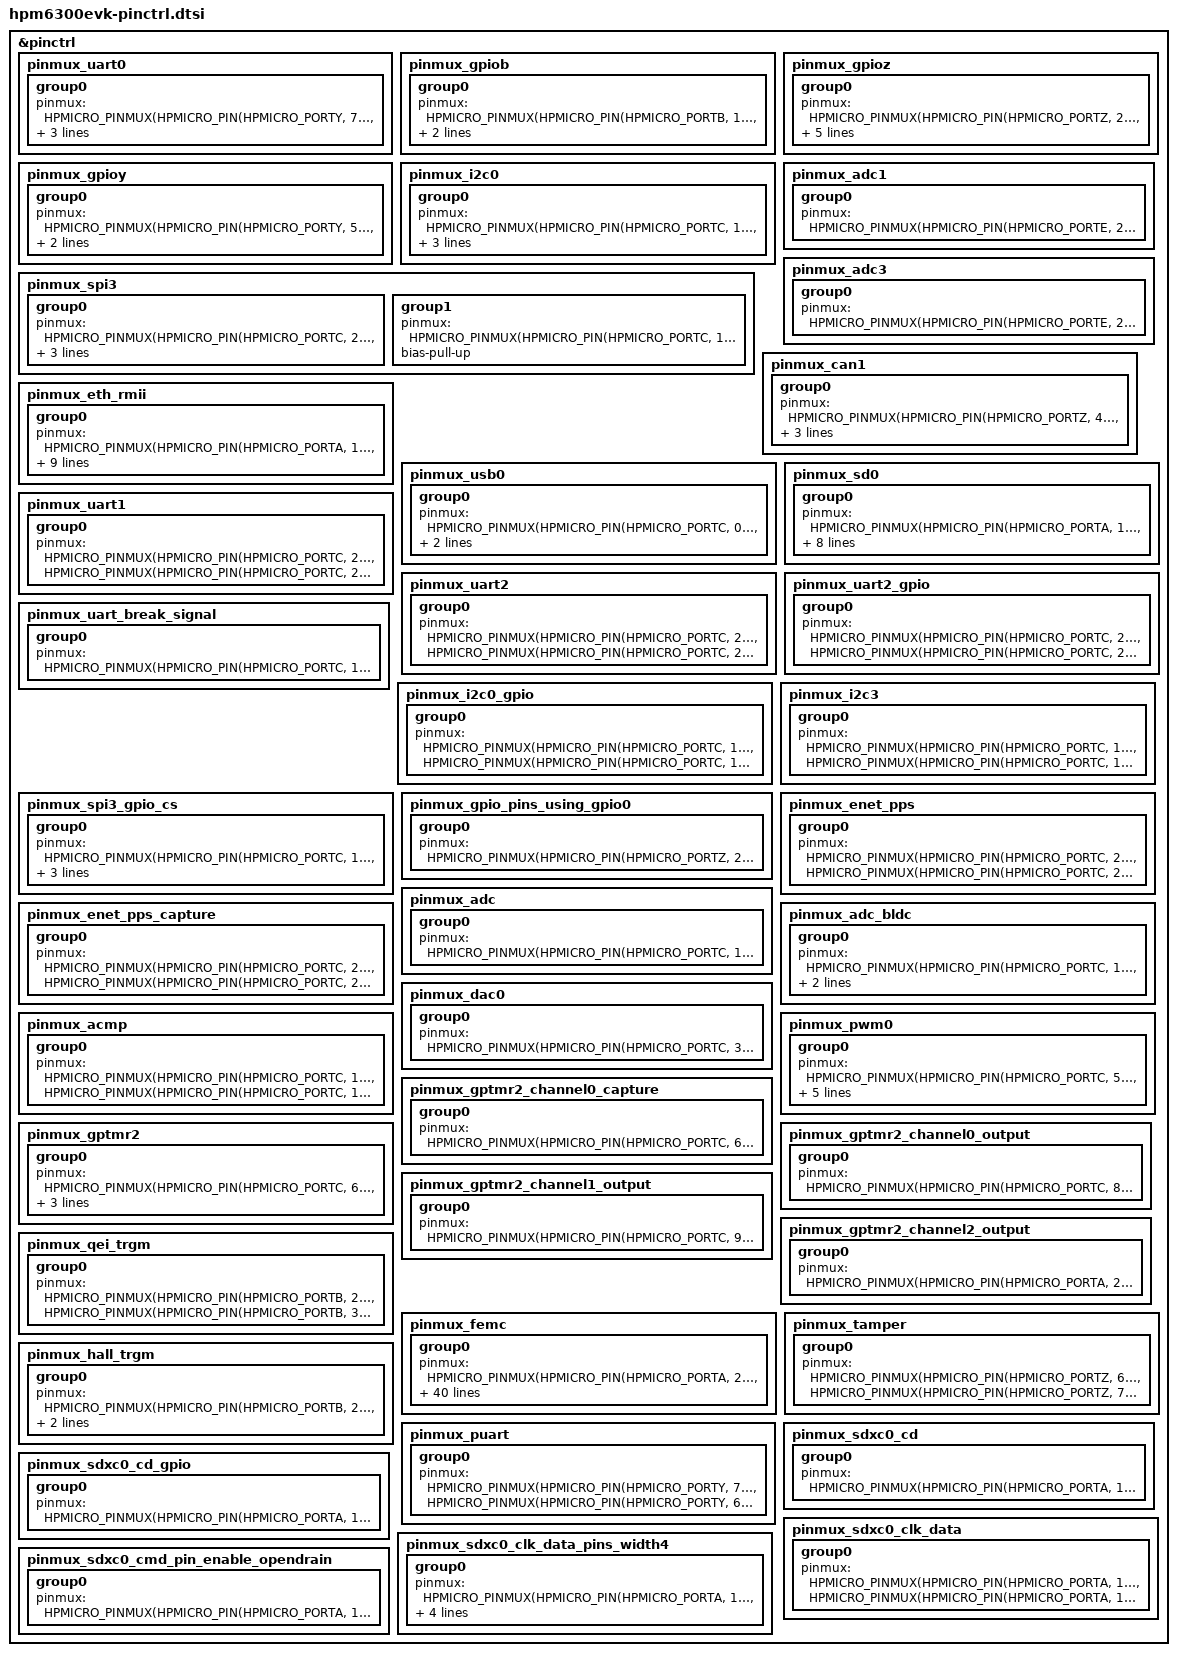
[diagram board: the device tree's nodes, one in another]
/*
* Copyright (c) 2026 HPMicro
* SPDX-License-Identifier: Apache-2.0
*/

#include "dt-bindings/pinctrl/hpmicro-pinctrl-common.h"

&pinctrl {
	pinmux_uart0: pinmux_uart0 {
		group0 {
			pinmux = <HPMICRO_PINMUX(HPMICRO_PIN(HPMICRO_PORTY, 7), IOC_TYPE_IOC, 0, 2)>,
				<HPMICRO_PINMUX(HPMICRO_PIN(HPMICRO_PORTY, 6), IOC_TYPE_IOC, 0, 2)>,
				<HPMICRO_PINMUX(HPMICRO_PIN(HPMICRO_PORTY, 7), IOC_TYPE_PIOC, 0, 3)>,
				<HPMICRO_PINMUX(HPMICRO_PIN(HPMICRO_PORTY, 6), IOC_TYPE_PIOC, 0, 3)>;
		};
	};

	pinmux_gpiob: pinmux_gpiob {
		group0 {
			pinmux = <HPMICRO_PINMUX(HPMICRO_PIN(HPMICRO_PORTB, 1), IOC_TYPE_IOC, 0, 0)>,
				<HPMICRO_PINMUX(HPMICRO_PIN(HPMICRO_PORTB, 19), IOC_TYPE_IOC, 0, 0)>;
			bias-pull-down;
		};
	};

	pinmux_gpioz: pinmux_gpioz {
		group0 {
			pinmux = <HPMICRO_PINMUX(HPMICRO_PIN(HPMICRO_PORTZ, 2), IOC_TYPE_IOC, 0, 0)>,
				<HPMICRO_PINMUX(HPMICRO_PIN(HPMICRO_PORTZ, 2), IOC_TYPE_BIOC, 0, 3)>;
			bias-pull-up;
			input-enable;
			keeper-capability-disable;
			input-schmitt-enable;
		};
	};

	pinmux_gpioy: pinmux_gpioy {
		group0 {
			pinmux = <HPMICRO_PINMUX(HPMICRO_PIN(HPMICRO_PORTY, 5), IOC_TYPE_IOC, 0, 0)>,
				<HPMICRO_PINMUX(HPMICRO_PIN(HPMICRO_PORTY, 5), IOC_TYPE_BIOC, 0, 3)>;
			bias-pull-up;
		};
	};

	pinmux_i2c0: pinmux_i2c0 {
		group0 {
			pinmux = <HPMICRO_PINMUX(HPMICRO_PIN(HPMICRO_PORTC, 13), IOC_TYPE_IOC, 0, 4)>,
				<HPMICRO_PINMUX(HPMICRO_PIN(HPMICRO_PORTC, 14), IOC_TYPE_IOC, 0, 4)>;
			drive-open-drain;
			input-enable;
		};
	};

	pinmux_spi3: pinmux_spi3 {
		group0 {
			pinmux = <HPMICRO_PINMUX(HPMICRO_PIN(HPMICRO_PORTC, 21), IOC_TYPE_IOC, 0, 5)>,
				<HPMICRO_PINMUX(HPMICRO_PIN(HPMICRO_PORTC, 19), IOC_TYPE_IOC, 0, 5)>,
				<HPMICRO_PINMUX(HPMICRO_PIN(HPMICRO_PORTC, 20), IOC_TYPE_IOC, 0, 5)>;
			input-enable;
		};

		group1 {
			pinmux = <HPMICRO_PINMUX(HPMICRO_PIN(HPMICRO_PORTC, 18), IOC_TYPE_IOC, 0, 0)>;
			bias-pull-up;
		};
	};

	pinmux_adc1: pinmux_adc1 {
		group0 {
			pinmux = <HPMICRO_PINMUX(HPMICRO_PIN(HPMICRO_PORTE, 21), IOC_TYPE_IOC, 1, 0)>;
		};
	};

	pinmux_adc3: pinmux_adc3 {
		group0 {
			pinmux = <HPMICRO_PINMUX(HPMICRO_PIN(HPMICRO_PORTE, 29), IOC_TYPE_IOC, 1, 0)>;
		};
	};

	pinmux_can1: pinmux_can1 {
		group0 {
			pinmux = <HPMICRO_PINMUX(HPMICRO_PIN(HPMICRO_PORTZ, 4), IOC_TYPE_IOC, 0, 7)>,
				<HPMICRO_PINMUX(HPMICRO_PIN(HPMICRO_PORTZ, 5), IOC_TYPE_IOC, 0, 7)>,
				<HPMICRO_PINMUX(HPMICRO_PIN(HPMICRO_PORTZ, 4), IOC_TYPE_BIOC, 0, 3)>,
				<HPMICRO_PINMUX(HPMICRO_PIN(HPMICRO_PORTZ, 5), IOC_TYPE_BIOC, 0, 3)>;
		};
	};

	pinmux_eth_rmii: pinmux_eth_rmii {
		group0 {
			pinmux = <HPMICRO_PINMUX(HPMICRO_PIN(HPMICRO_PORTA, 16), IOC_TYPE_IOC, 0, 19)>,
				<HPMICRO_PINMUX(HPMICRO_PIN(HPMICRO_PORTA, 15), IOC_TYPE_IOC, 0, 19)>,
				<HPMICRO_PINMUX(HPMICRO_PIN(HPMICRO_PORTA, 18), IOC_TYPE_IOC, 0, 18)>,
				<HPMICRO_PINMUX(HPMICRO_PIN(HPMICRO_PORTA, 17), IOC_TYPE_IOC, 0, 18)>,
				<HPMICRO_PINMUX(HPMICRO_PIN(HPMICRO_PORTA, 19), IOC_TYPE_IOC, 0, 18)>,
				<HPMICRO_PINMUX(HPMICRO_PIN(HPMICRO_PORTA, 20), IOC_TYPE_IOC, 0, 18)>,
				<HPMICRO_PINMUX(HPMICRO_PIN(HPMICRO_PORTA, 21), IOC_TYPE_IOC, 0, 18)>,
				<HPMICRO_PINMUX(HPMICRO_PIN(HPMICRO_PORTA, 23), IOC_TYPE_IOC, 0, 18)>,
				<HPMICRO_PINMUX(HPMICRO_PIN(HPMICRO_PORTA, 22), IOC_TYPE_IOC, 0, 18)>;
			input-enable;
		};
	};

	pinmux_usb0: pinmux_usb0 {
		group0 {
			pinmux = <HPMICRO_PINMUX(HPMICRO_PIN(HPMICRO_PORTC, 0), IOC_TYPE_IOC, 0, 24)>,
				<HPMICRO_PINMUX(HPMICRO_PIN(HPMICRO_PORTC, 1), IOC_TYPE_IOC, 0, 24)>,
				<HPMICRO_PINMUX(HPMICRO_PIN(HPMICRO_PORTC, 2), IOC_TYPE_IOC, 0, 24)>;
		};
	};

	pinmux_sd0: pinmux_sd0 {
		group0 {
			pinmux = <HPMICRO_PINMUX(HPMICRO_PIN(HPMICRO_PORTA, 10), IOC_TYPE_IOC, 0, 17)>,
				<HPMICRO_PINMUX(HPMICRO_PIN(HPMICRO_PORTA, 11), IOC_TYPE_IOC, 0, 17)>,
				<HPMICRO_PINMUX(HPMICRO_PIN(HPMICRO_PORTA, 12), IOC_TYPE_IOC, 0, 17)>,
				<HPMICRO_PINMUX(HPMICRO_PIN(HPMICRO_PORTA, 13), IOC_TYPE_IOC, 0, 17)>,
				<HPMICRO_PINMUX(HPMICRO_PIN(HPMICRO_PORTA, 8), IOC_TYPE_IOC, 0, 17)>,
				<HPMICRO_PINMUX(HPMICRO_PIN(HPMICRO_PORTA, 9), IOC_TYPE_IOC, 0, 17)>;
			input-enable;
			bias-pull-up;
			drive-strength = "r111";
		};
	};

	pinmux_uart1: pinmux_uart1 {
		group0 {
			pinmux = <HPMICRO_PINMUX(HPMICRO_PIN(HPMICRO_PORTC, 24), IOC_TYPE_IOC, 0, 2)>,
				<HPMICRO_PINMUX(HPMICRO_PIN(HPMICRO_PORTC, 25), IOC_TYPE_IOC, 0, 2)>;
		};
	};

	pinmux_uart2: pinmux_uart2 {
		group0 {
			pinmux = <HPMICRO_PINMUX(HPMICRO_PIN(HPMICRO_PORTC, 26), IOC_TYPE_IOC, 0, 2)>,
				<HPMICRO_PINMUX(HPMICRO_PIN(HPMICRO_PORTC, 27), IOC_TYPE_IOC, 0, 2)>;
		};
	};

	pinmux_uart2_gpio: pinmux_uart2_gpio {
		group0 {
			pinmux = <HPMICRO_PINMUX(HPMICRO_PIN(HPMICRO_PORTC, 26), IOC_TYPE_IOC, 0, 0)>,
				<HPMICRO_PINMUX(HPMICRO_PIN(HPMICRO_PORTC, 27), IOC_TYPE_IOC, 0, 0)>;
		};
	};

	pinmux_uart_break_signal: pinmux_uart_break_signal {
		group0 {
			pinmux = <HPMICRO_PINMUX(HPMICRO_PIN(HPMICRO_PORTC, 18), IOC_TYPE_IOC, 0, 0)>;
		};
	};

	pinmux_i2c0_gpio: pinmux_i2c0_gpio {
		group0 {
			pinmux = <HPMICRO_PINMUX(HPMICRO_PIN(HPMICRO_PORTC, 13), IOC_TYPE_IOC, 0, 0)>,
				<HPMICRO_PINMUX(HPMICRO_PIN(HPMICRO_PORTC, 14), IOC_TYPE_IOC, 0, 0)>;
		};
	};

	pinmux_i2c3: pinmux_i2c3 {
		group0 {
			pinmux = <HPMICRO_PINMUX(HPMICRO_PIN(HPMICRO_PORTC, 11), IOC_TYPE_IOC, 0, 4)>,
				<HPMICRO_PINMUX(HPMICRO_PIN(HPMICRO_PORTC, 12), IOC_TYPE_IOC, 0, 4)>;
		};
	};

	pinmux_spi3_gpio_cs: pinmux_spi3_gpio_cs {
		group0 {
			pinmux = <HPMICRO_PINMUX(HPMICRO_PIN(HPMICRO_PORTC, 18), IOC_TYPE_IOC, 0, 0)>,
				<HPMICRO_PINMUX(HPMICRO_PIN(HPMICRO_PORTC, 21), IOC_TYPE_IOC, 0, 5)>,
				<HPMICRO_PINMUX(HPMICRO_PIN(HPMICRO_PORTC, 19), IOC_TYPE_IOC, 0, 5)>,
				<HPMICRO_PINMUX(HPMICRO_PIN(HPMICRO_PORTC, 20), IOC_TYPE_IOC, 0, 5)>;
		};
	};

	pinmux_gpio_pins_using_gpio0: pinmux_gpio_pins_using_gpio0 {
		group0 {
			pinmux =
				<HPMICRO_PINMUX(HPMICRO_PIN(HPMICRO_PORTZ, 2), IOC_TYPE_BIOC, 0, 3)>;
		};
	};

	pinmux_enet_pps: pinmux_enet_pps {
		group0 {
			pinmux = <HPMICRO_PINMUX(HPMICRO_PIN(HPMICRO_PORTC, 21), IOC_TYPE_IOC, 0, 19)>,
				<HPMICRO_PINMUX(HPMICRO_PIN(HPMICRO_PORTC, 20), IOC_TYPE_IOC, 0, 19)>;
		};
	};

	pinmux_enet_pps_capture: pinmux_enet_pps_capture {
		group0 {
			pinmux = <HPMICRO_PINMUX(HPMICRO_PIN(HPMICRO_PORTC, 27), IOC_TYPE_IOC, 0, 19)>,
				<HPMICRO_PINMUX(HPMICRO_PIN(HPMICRO_PORTC, 26), IOC_TYPE_IOC, 0, 19)>;
		};
	};

	pinmux_adc: pinmux_adc {
		group0 {
			pinmux = <HPMICRO_PINMUX(HPMICRO_PIN(HPMICRO_PORTC, 10), IOC_TYPE_IOC, 1, 0)>;
		};
	};

	pinmux_adc_bldc: pinmux_adc_bldc {
		group0 {
			pinmux = <HPMICRO_PINMUX(HPMICRO_PIN(HPMICRO_PORTC, 16), IOC_TYPE_IOC, 1, 0)>,
				<HPMICRO_PINMUX(HPMICRO_PIN(HPMICRO_PORTC, 17), IOC_TYPE_IOC, 1, 0)>,
				<HPMICRO_PINMUX(HPMICRO_PIN(HPMICRO_PORTC, 22), IOC_TYPE_IOC, 1, 0)>;
		};
	};

	pinmux_dac0: pinmux_dac0 {
		group0 {
			pinmux = <HPMICRO_PINMUX(HPMICRO_PIN(HPMICRO_PORTC, 3), IOC_TYPE_IOC, 1, 0)>;
		};
	};

	pinmux_acmp: pinmux_acmp {
		group0 {
			pinmux = <HPMICRO_PINMUX(HPMICRO_PIN(HPMICRO_PORTC, 16), IOC_TYPE_IOC, 1, 0)>,
				<HPMICRO_PINMUX(HPMICRO_PIN(HPMICRO_PORTC, 15), IOC_TYPE_IOC, 0, 16)>;
		};
	};

	pinmux_pwm0: pinmux_pwm0 {
		group0 {
			pinmux = <HPMICRO_PINMUX(HPMICRO_PIN(HPMICRO_PORTC, 5), IOC_TYPE_IOC, 0, 16)>,
				<HPMICRO_PINMUX(HPMICRO_PIN(HPMICRO_PORTC, 3), IOC_TYPE_IOC, 0, 16)>,
				<HPMICRO_PINMUX(HPMICRO_PIN(HPMICRO_PORTC, 1), IOC_TYPE_IOC, 0, 16)>,
				<HPMICRO_PINMUX(HPMICRO_PIN(HPMICRO_PORTC, 4), IOC_TYPE_IOC, 0, 16)>,
				<HPMICRO_PINMUX(HPMICRO_PIN(HPMICRO_PORTC, 2), IOC_TYPE_IOC, 0, 16)>,
				<HPMICRO_PINMUX(HPMICRO_PIN(HPMICRO_PORTC, 0), IOC_TYPE_IOC, 0, 16)>;
		};
	};

	pinmux_gptmr2: pinmux_gptmr2 {
		group0 {
			pinmux = <HPMICRO_PINMUX(HPMICRO_PIN(HPMICRO_PORTC, 6), IOC_TYPE_IOC, 0, 1)>,
				<HPMICRO_PINMUX(HPMICRO_PIN(HPMICRO_PORTC, 8), IOC_TYPE_IOC, 0, 1)>,
				<HPMICRO_PINMUX(HPMICRO_PIN(HPMICRO_PORTC, 9), IOC_TYPE_IOC, 0, 1)>,
				<HPMICRO_PINMUX(HPMICRO_PIN(HPMICRO_PORTA, 24), IOC_TYPE_IOC, 0, 16)>;
		};
	};

	pinmux_gptmr2_channel0_capture: pinmux_gptmr2_channel0_capture {
		group0 {
			pinmux = <HPMICRO_PINMUX(HPMICRO_PIN(HPMICRO_PORTC, 6), IOC_TYPE_IOC, 0, 1)>;
		};
	};

	pinmux_gptmr2_channel0_output: pinmux_gptmr2_channel0_output {
		group0 {
			pinmux = <HPMICRO_PINMUX(HPMICRO_PIN(HPMICRO_PORTC, 8), IOC_TYPE_IOC, 0, 1)>;
		};
	};

	pinmux_gptmr2_channel1_output: pinmux_gptmr2_channel1_output {
		group0 {
			pinmux = <HPMICRO_PINMUX(HPMICRO_PIN(HPMICRO_PORTC, 9), IOC_TYPE_IOC, 0, 1)>;
		};
	};

	pinmux_gptmr2_channel2_output: pinmux_gptmr2_channel2_output {
		group0 {
			pinmux = <HPMICRO_PINMUX(HPMICRO_PIN(HPMICRO_PORTA, 24), IOC_TYPE_IOC, 0, 16)>;
		};
	};

	pinmux_qei_trgm: pinmux_qei_trgm {
		group0 {
			pinmux = <HPMICRO_PINMUX(HPMICRO_PIN(HPMICRO_PORTB, 29), IOC_TYPE_IOC, 0, 16)>,
				<HPMICRO_PINMUX(HPMICRO_PIN(HPMICRO_PORTB, 30), IOC_TYPE_IOC, 0, 16)>;
		};
	};

	pinmux_femc: pinmux_femc {
		group0 {
			pinmux = <HPMICRO_PINMUX(HPMICRO_PIN(HPMICRO_PORTA, 25), IOC_TYPE_IOC, 0, 12)>,
				<HPMICRO_PINMUX(HPMICRO_PIN(HPMICRO_PORTA, 26), IOC_TYPE_IOC, 0, 12)>,
				<HPMICRO_PINMUX(HPMICRO_PIN(HPMICRO_PORTA, 27), IOC_TYPE_IOC, 0, 12)>,
				<HPMICRO_PINMUX(HPMICRO_PIN(HPMICRO_PORTA, 28), IOC_TYPE_IOC, 0, 12)>,
				<HPMICRO_PINMUX(HPMICRO_PIN(HPMICRO_PORTA, 29), IOC_TYPE_IOC, 0, 12)>,
				<HPMICRO_PINMUX(HPMICRO_PIN(HPMICRO_PORTA, 30), IOC_TYPE_IOC, 0, 12)>,
				<HPMICRO_PINMUX(HPMICRO_PIN(HPMICRO_PORTA, 31), IOC_TYPE_IOC, 0, 12)>,
				<HPMICRO_PINMUX(HPMICRO_PIN(HPMICRO_PORTB, 0), IOC_TYPE_IOC, 0, 12)>,
				<HPMICRO_PINMUX(HPMICRO_PIN(HPMICRO_PORTB, 1), IOC_TYPE_IOC, 0, 12)>,
				<HPMICRO_PINMUX(HPMICRO_PIN(HPMICRO_PORTB, 2), IOC_TYPE_IOC, 0, 12)>,
				<HPMICRO_PINMUX(HPMICRO_PIN(HPMICRO_PORTB, 3), IOC_TYPE_IOC, 0, 12)>,
				<HPMICRO_PINMUX(HPMICRO_PIN(HPMICRO_PORTB, 4), IOC_TYPE_IOC, 0, 12)>,
				<HPMICRO_PINMUX(HPMICRO_PIN(HPMICRO_PORTB, 5), IOC_TYPE_IOC, 0, 12)>,
				<HPMICRO_PINMUX(HPMICRO_PIN(HPMICRO_PORTB, 6), IOC_TYPE_IOC, 0, 12)>,
				<HPMICRO_PINMUX(HPMICRO_PIN(HPMICRO_PORTB, 7), IOC_TYPE_IOC, 0, 12)>,
				<HPMICRO_PINMUX(HPMICRO_PIN(HPMICRO_PORTB, 8), IOC_TYPE_IOC, 0, 12)>,
				<HPMICRO_PINMUX(HPMICRO_PIN(HPMICRO_PORTB, 9), IOC_TYPE_IOC, 0, 12)>,
				<HPMICRO_PINMUX(HPMICRO_PIN(HPMICRO_PORTB, 10), IOC_TYPE_IOC, 0, 12)>,
				<HPMICRO_PINMUX(HPMICRO_PIN(HPMICRO_PORTB, 11), IOC_TYPE_IOC, 0, 12)>,
				<HPMICRO_PINMUX(HPMICRO_PIN(HPMICRO_PORTB, 12), IOC_TYPE_IOC, 0, 12)>,
				<HPMICRO_PINMUX(HPMICRO_PIN(HPMICRO_PORTB, 13), IOC_TYPE_IOC, 0, 12)>,
				<HPMICRO_PINMUX(HPMICRO_PIN(HPMICRO_PORTB, 14), IOC_TYPE_IOC, 0, 12)>,
				<HPMICRO_PINMUX(HPMICRO_PIN(HPMICRO_PORTB, 15), IOC_TYPE_IOC, 0, 12)>,
				<HPMICRO_PINMUX(HPMICRO_PIN(HPMICRO_PORTB, 16), IOC_TYPE_IOC, 0, 12)>,
				<HPMICRO_PINMUX(HPMICRO_PIN(HPMICRO_PORTB, 17), IOC_TYPE_IOC, 0, 12)>,
				<HPMICRO_PINMUX(HPMICRO_PIN(HPMICRO_PORTB, 18), IOC_TYPE_IOC, 0, 12)>,
				<HPMICRO_PINMUX(HPMICRO_PIN(HPMICRO_PORTB, 19), IOC_TYPE_IOC, 0, 12)>,
				<HPMICRO_PINMUX(HPMICRO_PIN(HPMICRO_PORTB, 20), IOC_TYPE_IOC, 0, 12)>,
				<HPMICRO_PINMUX(HPMICRO_PIN(HPMICRO_PORTB, 21), IOC_TYPE_IOC, 0, 12)>,
				<HPMICRO_PINMUX(HPMICRO_PIN(HPMICRO_PORTB, 22), IOC_TYPE_IOC, 0, 12)>,
				<HPMICRO_PINMUX(HPMICRO_PIN(HPMICRO_PORTB, 23), IOC_TYPE_IOC, 0, 12)>,
				<HPMICRO_PINMUX(HPMICRO_PIN(HPMICRO_PORTB, 24), IOC_TYPE_IOC, 0, 12)>,
				<HPMICRO_PINMUX(HPMICRO_PIN(HPMICRO_PORTB, 25), IOC_TYPE_IOC, 0, 12)>,
				<HPMICRO_PINMUX(HPMICRO_PIN(HPMICRO_PORTB, 26), IOC_TYPE_IOC, 0, 12)>,
				<HPMICRO_PINMUX(HPMICRO_PIN(HPMICRO_PORTB, 27), IOC_TYPE_IOC, 0, 12)>,
				<HPMICRO_PINMUX(HPMICRO_PIN(HPMICRO_PORTB, 28), IOC_TYPE_IOC, 0, 12)>,
				<HPMICRO_PINMUX(HPMICRO_PIN(HPMICRO_PORTB, 29), IOC_TYPE_IOC, 0, 12)>,
				<HPMICRO_PINMUX(HPMICRO_PIN(HPMICRO_PORTB, 30), IOC_TYPE_IOC, 0, 12)>,
				<HPMICRO_PINMUX(HPMICRO_PIN(HPMICRO_PORTB, 31), IOC_TYPE_IOC, 0, 12)>,
				<HPMICRO_PINMUX(HPMICRO_PIN(HPMICRO_PORTA, 23), IOC_TYPE_IOC, 0, 12)>,
				<HPMICRO_PINMUX(HPMICRO_PIN(HPMICRO_PORTX, 7), IOC_TYPE_IOC, 0, 12)>;
		};
	};

	pinmux_tamper: pinmux_tamper {
		group0 {
			pinmux = <HPMICRO_PINMUX(HPMICRO_PIN(HPMICRO_PORTZ, 6), IOC_TYPE_BIOC, 0, 2)>,
				<HPMICRO_PINMUX(HPMICRO_PIN(HPMICRO_PORTZ, 7), IOC_TYPE_BIOC, 0, 2)>;
		};
	};

	pinmux_hall_trgm: pinmux_hall_trgm {
		group0 {
			pinmux = <HPMICRO_PINMUX(HPMICRO_PIN(HPMICRO_PORTB, 26), IOC_TYPE_IOC, 0, 16)>,
				<HPMICRO_PINMUX(HPMICRO_PIN(HPMICRO_PORTB, 27), IOC_TYPE_IOC, 0, 16)>,
				<HPMICRO_PINMUX(HPMICRO_PIN(HPMICRO_PORTB, 28), IOC_TYPE_IOC, 0, 16)>;
		};
	};

	pinmux_puart: pinmux_puart {
		group0 {
			pinmux = <HPMICRO_PINMUX(HPMICRO_PIN(HPMICRO_PORTY, 7), IOC_TYPE_PIOC, 0, 1)>,
				<HPMICRO_PINMUX(HPMICRO_PIN(HPMICRO_PORTY, 6), IOC_TYPE_PIOC, 0, 1)>;
		};
	};

	pinmux_sdxc0_cd: pinmux_sdxc0_cd {
		group0 {
			pinmux = <HPMICRO_PINMUX(HPMICRO_PIN(HPMICRO_PORTA, 14), IOC_TYPE_IOC, 0, 17)>;
		};
	};

	pinmux_sdxc0_cd_gpio: pinmux_sdxc0_cd_gpio {
		group0 {
			pinmux = <HPMICRO_PINMUX(HPMICRO_PIN(HPMICRO_PORTA, 14), IOC_TYPE_IOC, 0, 0)>;
		};
	};

	pinmux_sdxc0_clk_data: pinmux_sdxc0_clk_data {
		group0 {
			pinmux = <HPMICRO_PINMUX(HPMICRO_PIN(HPMICRO_PORTA, 11), IOC_TYPE_IOC, 0, 17)>,
				<HPMICRO_PINMUX(HPMICRO_PIN(HPMICRO_PORTA, 12), IOC_TYPE_IOC, 0, 17)>;
		};
	};

	pinmux_sdxc0_clk_data_pins_width4: pinmux_sdxc0_clk_data_pins_width4 {
		group0 {
			pinmux = <HPMICRO_PINMUX(HPMICRO_PIN(HPMICRO_PORTA, 13), IOC_TYPE_IOC, 0, 17)>,
				<HPMICRO_PINMUX(HPMICRO_PIN(HPMICRO_PORTA, 8), IOC_TYPE_IOC, 0, 17)>,
				<HPMICRO_PINMUX(HPMICRO_PIN(HPMICRO_PORTA, 9), IOC_TYPE_IOC, 0, 17)>,
				<HPMICRO_PINMUX(HPMICRO_PIN(HPMICRO_PORTA, 11), IOC_TYPE_IOC, 0, 17)>,
				<HPMICRO_PINMUX(HPMICRO_PIN(HPMICRO_PORTA, 12), IOC_TYPE_IOC, 0, 17)>;
		};
	};

	pinmux_sdxc0_cmd_pin_enable_opendrain: pinmux_sdxc0_cmd_pin_enable_opendrain {
		group0 {
			pinmux = <HPMICRO_PINMUX(HPMICRO_PIN(HPMICRO_PORTA, 10), IOC_TYPE_IOC, 0, 17)>;
		};
	};
};
